# S6E1C3xB register map
Vendor: Cypress; File version: 2.1
CPU: CM0PLUS r0p1, little endian, no MPU, no FPU, 2 interrupt priority bits
Registers are 32-bit, read-write, reset 0x0 unless marked. A register's access mark holds for its fields unless they carry their own. Offsets are from the block's base; [hi:lo] are bit positions; {n}, {i} and the like mark numbered series.

## SBSSR — Software-based Simultaneous Startup Register
Base 0x40025F00
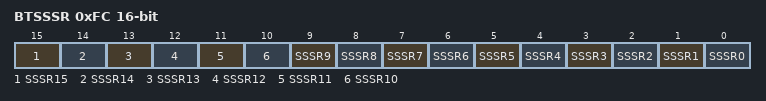
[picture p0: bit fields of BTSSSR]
0xFC BTSSSR 16-bit wo — Software-based Simultaneous Startup Register [BHW]
  [15] SSSR15 — Software-based simultaneous startup bit of Ch.15
  [14] SSSR14 — Software-based simultaneous startup bit of Ch.14
  [13] SSSR13 — Software-based simultaneous startup bit of Ch.13
  [12] SSSR12 — Software-based simultaneous startup bit of Ch.12
  [11] SSSR11 — Software-based simultaneous startup bit of Ch.11
  [10] SSSR10 — Software-based simultaneous startup bit of Ch.10
  [9] SSSR9 — Software-based simultaneous startup bit of Ch.9
  [8] SSSR8 — Software-based simultaneous startup bit of Ch.8
  [7] SSSR7 — Software-based simultaneous startup bit of Ch.7
  [6] SSSR6 — Software-based simultaneous startup bit of Ch.6
  [5] SSSR5 — Software-based simultaneous startup bit of Ch.5
  [4] SSSR4 — Software-based simultaneous startup bit of Ch.4
  [3] SSSR3 — Software-based simultaneous startup bit of Ch.3
  [2] SSSR2 — Software-based simultaneous startup bit of Ch.2
  [1] SSSR1 — Software-based simultaneous startup bit of Ch.1
  [0] SSSR0 — Software-based simultaneous startup bit of Ch.0

## CRTRIM — CR Trimming Registers
Base 0x4002E000
0x00 MCR_PSR 8-bit reset 0x1 — High-speed CR Oscillation Frequency Division Setup Register [BHW]
  [2:0] CSR — High-speed CR oscillation frequency division ratio setting bits
0x04 MCR_FTRM 16-bit reset 0x1EF — High-speed CR Oscillation Frequency Trimming Register [BHW]
  [9:0] TRD — Frequency trimming setup bits
0x08 MCR_TTRM 8-bit reset 0x7F — High-speed CR Oscillation Temperature Trimming Setup Register [BHW]
  [6:0] TRT — Temperature trimming setup bits
0x0C MCR_RLR reset 0x1 — High-Speed CR Oscillation Register Write-Protect Register [BHW]
  [31:0] TRMLCK — Register write-protect bits

## INTREQ — Interrupts
Base 0x40031000
0x08 VIR_OFFSET — Vector Indicate Register Offset Register [BHW]
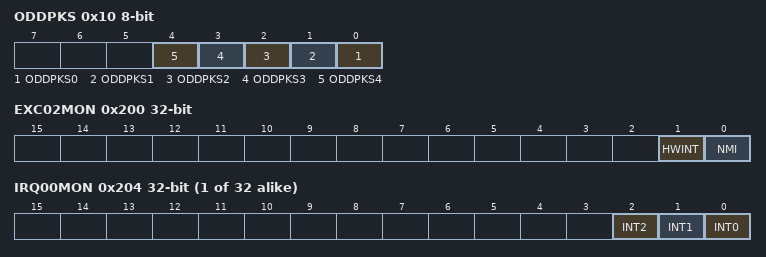
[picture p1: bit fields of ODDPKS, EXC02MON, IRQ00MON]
0x10 ODDPKS 8-bit — USB ch.0 Odd Packet Size DMA Enable Register [BHW]
  [n] ODDPKS{n} (n=0..4) — The bit width of the last transfer data is converted to Byte if the transfer destination address of DMAC is USB.EP{n+1}DT
0x200 EXC02MON ro — EXC02 Batch Read Register [BHW]
  [1] HWINT — Hardware watchdog timer interrupt request
  [0] NMI — NMIX external pin interrupt request
{0x204+4i} IRQ{i:02}MON ro (i=0..31) — IRQ{i:02} Batch Read Register [BHW]
  [2] INT2 — Interrupt request indication from the interrupt assigned to Bit2 of IRQ{i:02}
  [1] INT1 — Interrupt request indication from the interrupt assigned to Bit1 of IRQ{i:02}
  [0] INT0 — Interrupt request indication from the interrupt assigned to Bit0 of IRQ{i:02}

## HDMICEC0 — HDMI-CEC ch.0
Base 0x40034000
Same registers: HDMICEC1 0x40034100
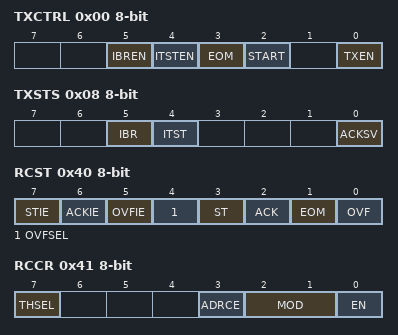
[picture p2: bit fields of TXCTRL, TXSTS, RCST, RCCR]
0x00 TXCTRL 8-bit — Transmission Control Register [BHW]
  [5] IBREN — Bus error detection interrupt enable bit
  [4] ITSTEN — transmission status interrupt enable bit
  [3] EOM — EOM setting bit
  [2] START — START setting bit
  [0] TXEN — Transmission operation enable bit
0x04 TXDATA 8-bit — Transmission Data Register [BHW]
  [7:0] TXDATA — Transmission Data
0x08 TXSTS 8-bit — Transmission Status Register [BHW]
  [5] IBR — Bus error detection interrupt request bit
  [4] ITST — Transmission status interrupt request bit
  [0] ACKSV ro — ACK cycle value bit
0x0C SFREE 8-bit — Signal Free Time Setting Register [BHW]
  [3:0] SFREE — Signal free time setting bits
0x40 RCST 8-bit — Reception Interrupt Control Register [BHW]
  [7] STIE — Start bit interrupt enable bit
  [6] ACKIE — ACK interrupt enable bit
  [5] OVFIE — Counter overflow interrupt enable bit
  [4] OVFSEL — Counter overflow detection condition setting bit
  [3] ST — Start bit detection bit
  [2] ACK — ACK: ACK detection bit
  [1] EOM — EOM detection bit
  [0] OVF — Counter overflow detection bit
0x41 RCCR 8-bit — Reception Control Register [BHW]
  [7] THSEL — Threshold selection bit
  [3] ADRCE — Address comparison enable bit
  [2:1] MOD — Operation mode setting bits
  [0] EN — Operation enable bit
0x44 RCDAHW 8-bit — Minimum Pulse Width Setting Register [BHW]
  [7:0] RCDAHW — Set the minimum pulse width duration
0x45 RCSHW 8-bit — Start Bit Detection Width Setting Register [BHW]
  [7:0] RCSHW — Set a duration of the start bit
0x49 RCDBHW 8-bit — Threshold Value Setting Register [BHW]
  [7:0] RCDBHW — Set the threshold value of data reception signal width
0x4C RCADR2 8-bit — Device Address Setting Register 2 [BHW]
  [4:0] RCADR2 — Device Address 2
0x4D RCADR1 8-bit — Device Address Setting Register 1 [BHW]
  [4:0] RCADR1 — Device Address 1
0x50 RCDTHL 8-bit ro — Data Save Register (High-Low) [BHW]
  [7:0] RCDTHL — Used to store received data
0x51 RCDTHH 8-bit ro — Data Save Register (High-High) [BHW]
  [7:0] RCDTHH — Used to store received data
0x54 RCDTLL 8-bit ro — Data Save Register (Low-Low) [BHW]
  [7:0] RCDTLL — Used to store received data
0x55 RCDTLH 8-bit ro — Data Save Register (Low-High) [BHW]
  [7:0] RCDTLH — Used to store received data
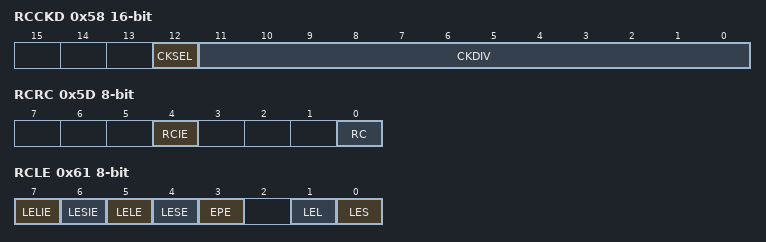
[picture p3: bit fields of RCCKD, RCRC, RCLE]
0x58 RCCKD 16-bit — Clock Division Setting Register [HW]
  [12] CKSEL — Operating clock selection bit
  [11:0] CKDIV — Operating clock division setting bits
0x5C RCRHW 8-bit — Repeat Code Detection Width Setting Register [BHW]
  [7:0] RCRHW — Set the detection width for a repeart code
0x5D RCRC 8-bit — Repeat Code Interrupt Control Register [BHW]
  [4] RCIE — Repeat Code Interrupt enable bit
  [0] RC — Repeat code detection flag bit
0x61 RCLE 8-bit — Data Bit Width Violation Control Register [BHW]
  [7] LELIE — Maximum data bit width violation interrupt enable bit
  [6] LESIE — Minimum data bit width violation interrupt enable bit
  [5] LELE — Maximum data bit width violation detection enable bit
  [4] LESE — Minimum data bit width violation detection enable bit
  [3] EPE — Error pulse output enable bit
  [1] LEL — Maximum data bit width violation detection flag bit
  [0] LES — Minimum data bit width violation detection flag bit
0x64 RCLESW 8-bit — Minimum Data Bit Width Setting Register [BHW]
  [7:0] RCLESW — Minimum data bit width setting bits
0x65 RCLELW 8-bit — Maximum Data Bit Width Setting Register [BHW]
  [7:0] RCLELW — Maximum data bit width setting bits
